AUTOSAR XML (schema 4-3-0)
package /RB/PT/PCT_MDG1_FlatView/SwComponentTypes
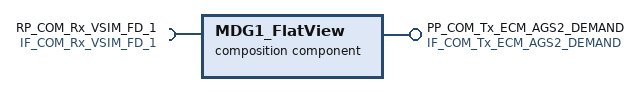
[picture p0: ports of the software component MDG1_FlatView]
  composition sw component type MDG1_FlatView
    provide port PP_COM_Tx_ECM_AGS2_DEMAND: provided-interface=IF_COM_Tx_ECM_AGS2_DEMAND
    require port RP_COM_Rx_VSIM_FD_1: required-interface=IF_COM_Rx_VSIM_FD_1
    component AC_CluRlyDigOutp: type=IoSigDioOutp_SwSStellantis
    connect CPT_ComDia_Dcm_Rte_Adapter.DataServices_D9E08_VeRPMR_n_EngSpdResl1 -> CPT_Dcm.DataServices_D9E08_VeRPMR_n_EngSpdResl1
